# STM32H573 register map
File version: 0.4
CPU: CM33 r0p0, little endian, MPU, FPU, 4 interrupt priority bits
Registers are 32-bit, read-write, reset 0x0 unless marked. A register's access mark holds for its fields unless they carry their own. Offsets are from the block's base; [hi:lo] are bit positions; {n}, {i} and the like mark numbered series.

## RCC (part 2 of 2) — Reset and clock controller
Base 0x44020C00
Same registers: SEC_RCC 0x54020C00
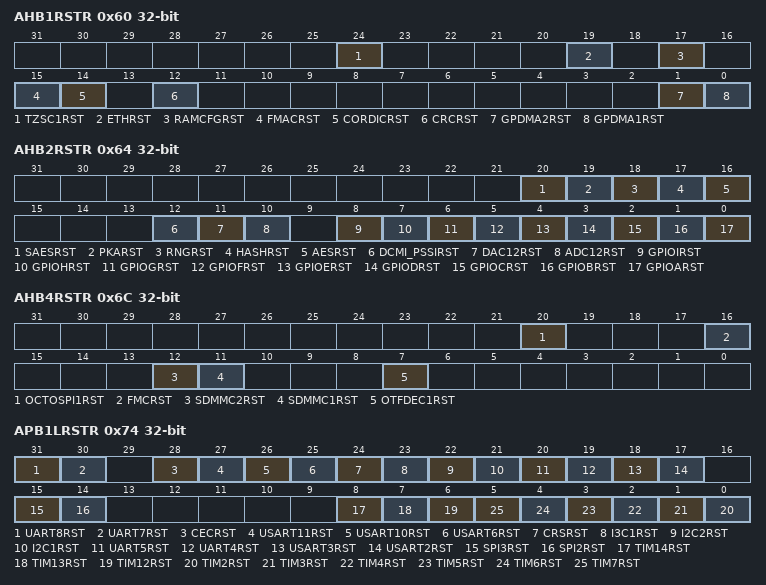
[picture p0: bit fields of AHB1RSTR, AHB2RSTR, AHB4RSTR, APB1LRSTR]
0x60 AHB1RSTR — RCC AHB1 reset register
  [24] TZSC1RST — TZSC1 reset Set and reset by software
  [19] ETHRST — ETHRST block reset Set and reset by software
  [17] RAMCFGRST — RAMCFG block reset Set and reset by software.
  [15] FMACRST — FMAC block reset Set and reset by software.
  [14] CORDICRST — CORDIC block reset Set and reset by software.
  [12] CRCRST — CRC block reset Set and reset by software.
  [1] GPDMA2RST — GPDMA2 block reset Set and reset by software.
  [0] GPDMA1RST — GPDMA1 block reset Set and reset by software.
0x64 AHB2RSTR — RCC AHB2 peripheral reset register
  [20] SAESRST — SAES block reset Set and reset by software.
  [19] PKARST — PKA block reset Set and reset by software.
  [18] RNGRST — RNG block reset Set and reset by software.
  [17] HASHRST — HASH block reset Set and reset by software.
  [16] AESRST — AES block reset Set and reset by software.
  [12] DCMI_PSSIRST — digital camera interface block reset (DCMI or PSSI depending which interface is active) Set and reset by software.
  [11] DAC12RST — DAC block reset Set and reset by software.
  [10] ADC12RST — ADC1 and 2 blocks reset Set and reset by software.
  [8] GPIOIRST — GPIOI block reset Set and reset by software.
  [7] GPIOHRST — GPIOH block reset Set and reset by software.
  [6] GPIOGRST — GPIOG block reset Set and reset by software.
  [5] GPIOFRST — GPIOF block reset Set and reset by software.
  [4] GPIOERST — GPIOE block reset Set and reset by software.
  [3] GPIODRST — GPIOD block reset Set and reset by software.
  [2] GPIOCRST — GPIOC block reset Set and reset by software.
  [1] GPIOBRST — GPIOB block reset Set and reset by software.
  [0] GPIOARST — GPIOA block reset Set and reset by software.
0x6C AHB4RSTR — RCC AHB4 peripheral reset register
  [20] OCTOSPI1RST — OCTOSPI1 block reset Set and reset by software.
  [16] FMCRST — FMC block reset Set and reset by software.
  [12] SDMMC2RST — SDMMC2 and SDMMC2 delay blocks reset Set and reset by software.
  [11] SDMMC1RST — SDMMC1 and SDMMC1 delay blocks reset Set and reset by software.
  [7] OTFDEC1RST — OTFDEC1 block reset Set and reset by software.
0x74 APB1LRSTR — RCC APB1 peripheral low reset register
  [31] UART8RST — UART8 block reset Set and reset by software.
  [30] UART7RST — UART7 block reset Set and reset by software.
  [28] CECRST — HDMI-CEC block reset Set and reset by software.
  [27] USART11RST — USART11 block reset Set and reset by software.
  [26] USART10RST — USART10 block reset Set and reset by software.
  [25] USART6RST — USART6 block reset Set and reset by software.
  [24] CRSRST — CRS block reset Set and reset by software.
  [23] I3C1RST — I3C1 block reset Set and reset by software.
  [22] I2C2RST — I2C2 block reset Set and reset by software.
  [21] I2C1RST — I2C1 block reset Set and reset by software.
  [20] UART5RST — UART5 block reset Set and reset by software.
  [19] UART4RST — UART4 block reset Set and reset by software.
  [18] USART3RST — USART3 block reset Set and reset by software.
  [17] USART2RST — USART2 block reset Set and reset by software.
  [15] SPI3RST — SPI3 block reset Set and reset by software.
  [14] SPI2RST — SPI2 block reset Set and reset by software.
  [8] TIM14RST — TIM14 block reset Set and reset by software.
  [7] TIM13RST — TIM13 block reset t Set and reset by software.
  [6] TIM12RST — TIM12 block reset Set and reset by software.
  [n-2] TIM{n}RST (n=2..7) — TIM{n} block reset Set and reset by software.
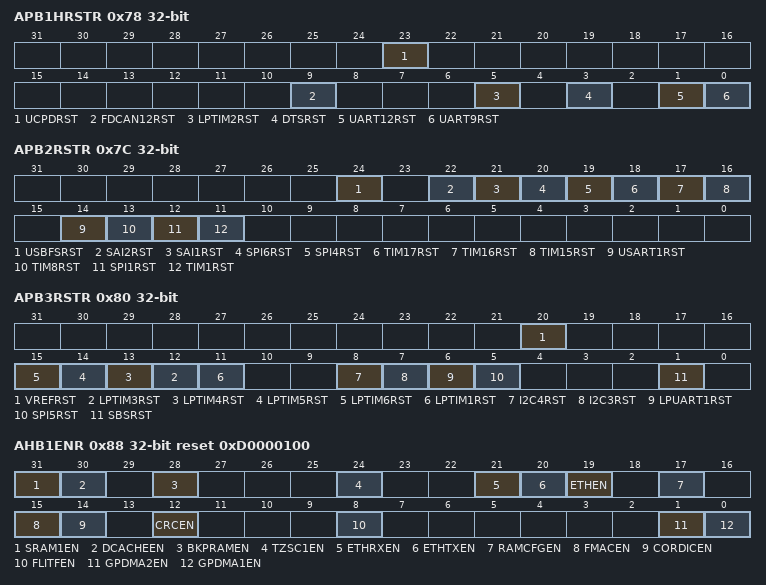
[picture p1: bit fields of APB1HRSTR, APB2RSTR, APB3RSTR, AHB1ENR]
0x78 APB1HRSTR — RCC APB1 peripheral high reset register
  [23] UCPDRST — UCPD block reset Set and reset by software.
  [9] FDCAN12RST — FDCAN1 and FDCAN2 blocks reset Set and reset by software.
  [5] LPTIM2RST — LPTIM2 block reset Set and reset by software.
  [3] DTSRST — DTS block reset Set and reset by software.
  [1] UART12RST — UART12 block reset Set and reset by software.
  [0] UART9RST — UART9 block reset Set and reset by software.
0x7C APB2RSTR — RCC APB2 peripheral reset register
  [24] USBFSRST — USBFS block reset Set and reset by software.
  [22] SAI2RST — SAI2 block reset Set and reset by software.
  [21] SAI1RST — SAI1 block reset Set and reset by software.
  [20] SPI6RST — SPI6 block reset Set and reset by software.
  [19] SPI4RST — SPI4 block reset Set and reset by software.
  [18] TIM17RST — TIM17 block reset Set and reset by software.
  [17] TIM16RST — TIM16 block reset Set and reset by software.
  [16] TIM15RST — TIM15 block reset Set and reset by software.
  [14] USART1RST — USART1 block reset Set and reset by software.
  [13] TIM8RST — TIM8 block reset Set and reset by software.
  [12] SPI1RST — SPI1 block reset Set and reset by software.
  [11] TIM1RST — TIM1 block reset Set and reset by software.
0x80 APB3RSTR — RCC APB4 peripheral reset register
  [20] VREFRST — VREF block reset Set and reset by software.
  [n+9] LPTIM{n}RST (n=3..6) — LPTIM{n} block reset Set and reset by software.
  [11] LPTIM1RST — LPTIM1 block reset Set and reset by software.
  [8] I2C4RST — I2C4 block reset Set and reset by software.
  [7] I2C3RST — I2C3 block reset Set and reset by software.
  [6] LPUART1RST — LPUART1 block reset Set and reset by software.
  [5] SPI5RST — SPI5 block reset Set and reset by software.
  [1] SBSRST — SBS block reset Set and reset by software.
0x88 AHB1ENR reset 0xD0000100 — RCC AHB1 peripherals clock register
  [31] SRAM1EN — SRAM1 clock enable Set and reset by software.
  [30] DCACHEEN — DCACHE clock enable Set and reset by software
  [28] BKPRAMEN — BKPRAM clock enable Set and reset by software
  [24] TZSC1EN — TZSC1 clock enable Set and reset by software
  [21] ETHRXEN — ETHRX clock enable Set and reset by software
  [20] ETHTXEN — ETHTX clock enable Set and reset by software
  [19] ETHEN — ETH clock enable Set and reset by software
  [17] RAMCFGEN — RAMCFG clock enable Set and reset by software.
  [15] FMACEN — FMAC clock enable Set and reset by software.
  [14] CORDICEN — CORDIC clock enable Set and reset by software.
  [12] CRCEN — CRC clock enable Set and reset by software.
  [8] FLITFEN — Flash interface clock enable Set and reset by software.
  [1] GPDMA2EN — GPDMA2 clock enable Set and reset by software.
  [0] GPDMA1EN — GPDMA1 clock enable Set and reset by software.
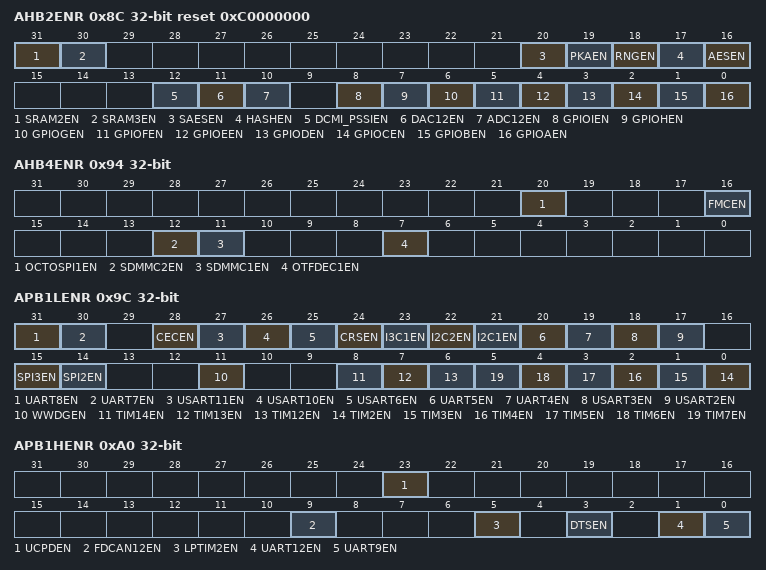
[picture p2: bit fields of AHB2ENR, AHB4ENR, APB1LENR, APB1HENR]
0x8C AHB2ENR reset 0xC0000000 — RCC AHB2 peripheral clock register
  [31] SRAM2EN — SRAM2 clock enable Set and reset by software.
  [30] SRAM3EN — SRAM3 clock enable Set and reset by software.
  [20] SAESEN — SAES clock enable Set and reset by software.
  [19] PKAEN — PKA clock enable Set and reset by software.
  [18] RNGEN — RNG clock enable Set and reset by software.
  [17] HASHEN — HASH clock enable Set and reset by software.
  [16] AESEN — AES clock enable Set and reset by software.
  [12] DCMI_PSSIEN — digital camera interface clock enable (DCMI or PSSI depending which interface is active) Set and reset by software.
  [11] DAC12EN — DAC clock enable Set and reset by software.
  [10] ADC12EN — ADC1 and 2 peripherals clock enabled Set and reset by software.
  [8] GPIOIEN — GPIOI clock enable Set and reset by software.
  [7] GPIOHEN — GPIOH clock enable Set and reset by software.
  [6] GPIOGEN — GPIOG clock enable Set and reset by software.
  [5] GPIOFEN — GPIOF clock enable Set and reset by software.
  [4] GPIOEEN — GPIOE clock enable Set and reset by software.
  [3] GPIODEN — GPIOD clock enable Set and reset by software.
  [2] GPIOCEN — GPIOC clock enable Set and reset by software.
  [1] GPIOBEN — GPIOB clock enable Set and reset by software.
  [0] GPIOAEN — GPIOA clock enable Set and reset by software.
0x94 AHB4ENR — RCC AHB4 peripheral clock register
  [20] OCTOSPI1EN — OCTOSPI1 clock enable Set and reset by software.
  [16] FMCEN — FMC clock enable Set and reset by software.
  [12] SDMMC2EN — SDMMC2 and SDMMC2 delay peripheral clock enabled Set and reset by software.
  [11] SDMMC1EN — SDMMC1 and SDMMC1 delay peripheral clock enable reset
  [7] OTFDEC1EN — OTFDEC1 clock enable Set and reset by software.
0x9C APB1LENR — RCC APB1 peripheral clock register
  [31] UART8EN — UART8 clock enable Set and reset by software.
  [30] UART7EN — UART7 clock enable Set and reset by software.
  [28] CECEN — HDMI-CEC clock enable Set and reset by software.
  [27] USART11EN — USART11 clock enable
  [26] USART10EN — USART10 clock enable Set and reset by software.
  [25] USART6EN — USART6 clock enable Set and reset by software.
  [24] CRSEN — CRS clock enable Set and reset by software.
  [23] I3C1EN — I3C1 clock enable Set and reset by software.
  [22] I2C2EN — I2C2 clock enable Set and reset by software.
  [21] I2C1EN — I2C1 clock enable Set and reset by software.
  [20] UART5EN — UART5 clock enable Set and reset by software.
  [19] UART4EN — UART4 clock enable Set and reset by software.
  [18] USART3EN — USART3 clock enable Set and reset by software.
  [17] USART2EN — USART2 clock enable Set and reset by software.
  [15] SPI3EN — SPI3 clock enable Set and reset by software.
  [14] SPI2EN — SPI2 clock enable Set and reset by software.
  [11] WWDGEN — WWDG clock enable Set and reset by software.
  [8] TIM14EN — TIM14 clock enable Set and reset by software.
  [7] TIM13EN — TIM13 clock enable Set and reset by software.
  [6] TIM12EN — TIM12 clock enable Set and reset by software.
  [n-2] TIM{n}EN (n=2..7) — TIM{n} clock enable Set and reset by software.
0xA0 APB1HENR — RCC APB1 peripheral clock register
  [23] UCPDEN — UCPD clock enable Set and reset by software.
  [9] FDCAN12EN — FDCAN1 and FDCAN2 peripheral clock enable Set and reset by software.
  [5] LPTIM2EN — LPTIM2 clock enable Set and reset by software.
  [3] DTSEN — DTS clock enable Set and reset by software.
  [1] UART12EN — UART12 clock enable Set and reset by software.
  [0] UART9EN — UART9 clock enable Set and reset by software.
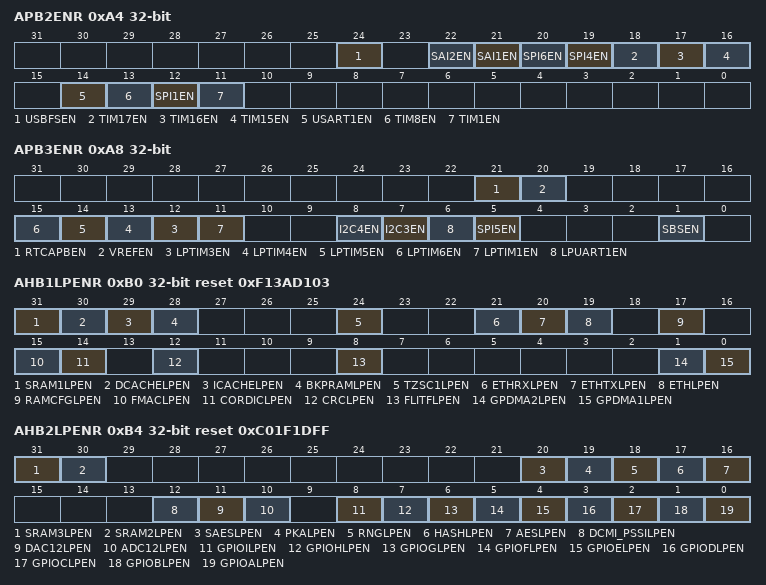
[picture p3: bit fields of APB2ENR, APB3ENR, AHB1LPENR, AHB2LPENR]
0xA4 APB2ENR — RCC APB2 peripheral clock register
  [24] USBFSEN — USBFS clock enable Set and reset by software.
  [22] SAI2EN — SAI2 clock enable Set and cleared by software.
  [21] SAI1EN — SAI1 clock enable Set and reset by software.
  [20] SPI6EN — SPI6 clock enable Set and reset by software.
  [19] SPI4EN — SPI4 clock enable Set and reset by software.
  [18] TIM17EN — TIM17 clock enable Set and reset by software.
  [17] TIM16EN — TIM16 clock enable Set and reset by software.
  [16] TIM15EN — TIM15 clock enable Set and reset by software.
  [14] USART1EN — USART1 clock enable Set and reset by software.
  [13] TIM8EN — TIM8 clock enable Set and reset by software.
  [12] SPI1EN — SPI1 clock enable Set and reset by software.
  [11] TIM1EN — TIM1 clock enable Set and reset by software.
0xA8 APB3ENR — RCC APB4 peripheral clock register
  [21] RTCAPBEN — RTC APB interface clock enable Set and reset by software.
  [20] VREFEN — VREF clock enable Set and reset by software.
  [n+9] LPTIM{n}EN (n=3..6) — LPTIM{n} clock enable Set and reset by software.
  [11] LPTIM1EN — LPTIM1 clock enable Set and reset by software.
  [8] I2C4EN — I2C4 clock enable Set and reset by software.
  [7] I2C3EN — I2C3 clock enable Set and reset by software.
  [6] LPUART1EN — LPUART1 clock enable Set and reset by software.
  [5] SPI5EN — SPI5 clock enable Set and reset by software.
  [1] SBSEN — SBS clock enable Set and reset by software.
0xB0 AHB1LPENR reset 0xF13AD103 — RCC AHB1 sleep clock register
  [31] SRAM1LPEN — SRAM1 clock enable during sleep mode Set and reset by software
  [30] DCACHELPEN — DCACHE clock enable during sleep mode Set and reset by software
  [29] ICACHELPEN — ICACHE clock enable during sleep mode Set and reset by software
  [28] BKPRAMLPEN — BKPRAM clock enable during sleep mode Set and reset by software
  [24] TZSC1LPEN — TZSC1 clock enable during sleep mode Set and reset by software
  [21] ETHRXLPEN — ETHRX clock enable during sleep mode Set and reset by software
  [20] ETHTXLPEN — ETHTX clock enable during sleep mode Set and reset by software
  [19] ETHLPEN — ETH clock enable during Sleep mode Set and reset by software
  [17] RAMCFGLPEN — RAMCFG clock enable during sleep mode Set and reset by software.
  [15] FMACLPEN — FMAC clock enable during sleep mode Set and reset by software.
  [14] CORDICLPEN — CORDIC clock enable during sleep mode Set and reset by software.
  [12] CRCLPEN — CRC clock enable during sleep mode Set and reset by software.
  [8] FLITFLPEN — Flash interface (FLITF) clock enable during sleep mode Set and reset by software.
  [1] GPDMA2LPEN — GPDMA2 clock enable during sleep mode Set and reset by software.
  [0] GPDMA1LPEN — GPDMA1 clock enable during sleep mode Set and reset by software.
0xB4 AHB2LPENR reset 0xC01F1DFF — RCC AHB2 sleep clock register
  [31] SRAM3LPEN — SRAM3 clock enable during sleep mode Set and reset by software.
  [30] SRAM2LPEN — SRAM2 clock enable during sleep mode Set and reset by software.
  [20] SAESLPEN — SAES clock enable during sleep mode Set and reset by software.
  [19] PKALPEN — PKA clock enable during sleep mode Set and reset by software.
  [18] RNGLPEN — RNG clock enable during sleep mode Set and reset by software.
  [17] HASHLPEN — HASH clock enable during sleep mode Set and reset by software.
  [16] AESLPEN — AES clock enable during sleep mode Set and reset by software.
  [12] DCMI_PSSILPEN — digital camera interface clock enable during sleep mode (DCMI or PSSI depending which interface is active) Set and reset by software.
  [11] DAC12LPEN — DAC clock enable during sleep mode Set and reset by software.
  [10] ADC12LPEN — ADC1 and 2 peripherals clock enable during sleep mode Set and reset by software.
  [8] GPIOILPEN — GPIOI clock enable during sleep mode Set and reset by software.
  [7] GPIOHLPEN — GPIOH clock enable during sleep mode Set and reset by software.
  [6] GPIOGLPEN — GPIOG clock enable during sleep mode Set and reset by software.
  [5] GPIOFLPEN — GPIOF clock enable during sleep mode Set and reset by software.
  [4] GPIOELPEN — GPIOE clock enable during sleep mode Set and reset by software.
  [3] GPIODLPEN — GPIOD clock enable during sleep mode Set and reset by software.
  [2] GPIOCLPEN — GPIOC clock enable during sleep mode Set and reset by software.
  [1] GPIOBLPEN — GPIOB clock enable during sleep mode Set and reset by software.
  [0] GPIOALPEN — GPIOA clock enable during sleep mode Set and reset by software.
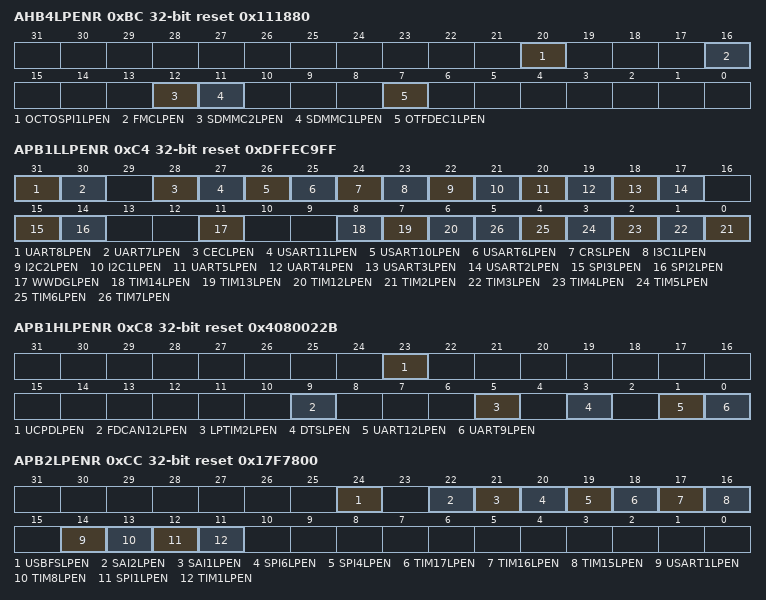
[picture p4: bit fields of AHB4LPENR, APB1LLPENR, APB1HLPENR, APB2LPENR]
0xBC AHB4LPENR reset 0x111880 — RCC AHB4 sleep clock register
  [20] OCTOSPI1LPEN — OCTOSPI1 clock enable during sleep mode Set and reset by software.
  [16] FMCLPEN — FMC clock enable during sleep mode Set and reset by software.
  [12] SDMMC2LPEN — SDMMC2 and SDMMC2 delay peripheral clock enable during sleep mode Set and reset by software.
  [11] SDMMC1LPEN — SDMMC1 and SDMMC1 delay peripheral clock enable during sleep mode Set and reset by software
  [7] OTFDEC1LPEN — OTFDEC1 clock enable during sleep mode Set and reset by software.
0xC4 APB1LLPENR reset 0xDFFEC9FF — RCC APB1 sleep clock register
  [31] UART8LPEN — UART8 clock enable during sleep mode Set and reset by software.
  [30] UART7LPEN — UART7 clock enable during sleep mode Set and reset by software.
  [28] CECLPEN — HDMI-CEC clock enable during sleep mode Set and reset by software.
  [27] USART11LPEN — USART11 clock enable during sleep mode Set and reset by software.
  [26] USART10LPEN — USART10 clock enable during sleep mode Set and reset by software.
  [25] USART6LPEN — USART6 clock enable during sleep mode Set and reset by software.
  [24] CRSLPEN — CRS clock enable during sleep mode Set and reset by software.
  [23] I3C1LPEN — I3C1 clock enable during sleep mode Set and reset by software.
  [22] I2C2LPEN — I2C2 clock enable during sleep mode Set and reset by software.
  [21] I2C1LPEN — I2C1 clock enable during sleep mode Set and reset by software.
  [20] UART5LPEN — UART5 clock enable during sleep mode Set and reset by software.
  [19] UART4LPEN — UART4 clock enable during sleep mode Set and reset by software.
  [18] USART3LPEN — USART3 clock enable during sleep mode Set and reset by software.
  [17] USART2LPEN — USART2 clock enable during sleep mode Set and reset by software.
  [15] SPI3LPEN — SPI3 clock enable during sleep mode Set and reset by software.
  [14] SPI2LPEN — SPI2 clock enable during sleep mode Set and reset by software.
  [11] WWDGLPEN — WWDG clock enable during sleep mode Set and reset by software.
  [8] TIM14LPEN — TIM14 clock enable during sleep mode Set and reset by software.
  [7] TIM13LPEN — TIM13 clock enable during sleep mode Set and reset by software.
  [6] TIM12LPEN — TIM12 clock enable during sleep mode Set and reset by software.
  [n-2] TIM{n}LPEN (n=2..7) — TIM{n} clock enable during sleep mode Set and reset by software.
0xC8 APB1HLPENR reset 0x4080022B — RCC APB1 sleep clock register
  [23] UCPDLPEN — UCPD clock enable during sleep mode Set and reset by software.
  [9] FDCAN12LPEN — FDCAN1 and FDCAN2 peripheral clock enable during sleep mode Set and reset by software.
  [5] LPTIM2LPEN — LPTIM2 clock enable during sleep mode Set and reset by software.
  [3] DTSLPEN — DTS clock enable during sleep mode Set and reset by software.
  [1] UART12LPEN — UART12 clock enable during sleep mode Set and reset by software.
  [0] UART9LPEN — UART9 clock enable during sleep mode Set and reset by software.
0xCC APB2LPENR reset 0x17F7800 — RCC APB2 sleep clock register
  [24] USBFSLPEN — USBFS clock enable during sleep mode Set and reset by software.
  [22] SAI2LPEN — SAI2 clock enable during sleep mode Set and reset by software.
  [21] SAI1LPEN — SAI1 clock enable during sleep mode Set and reset by software.
  [20] SPI6LPEN — SPI6 clock enable during sleep mode Set and reset by software.
  [19] SPI4LPEN — SPI4 clock enable during sleep mode Set and reset by software.
  [18] TIM17LPEN — TIM17 clock enable during sleep mode Set and reset by software.
  [17] TIM16LPEN — TIM16 clock enable during sleep mode Set and reset by software.
  [16] TIM15LPEN — TIM15 clock enable during sleep mode Set and reset by software.
  [14] USART1LPEN — USART1 clock enable during sleep mode Set and reset by software.
  [13] TIM8LPEN — TIM8 clock enable during sleep mode Set and reset by software.
  [12] SPI1LPEN — SPI1 clock enable during sleep mode Set and reset by software.
  [11] TIM1LPEN — TIM1 clock enable during sleep mode Set and reset by software.
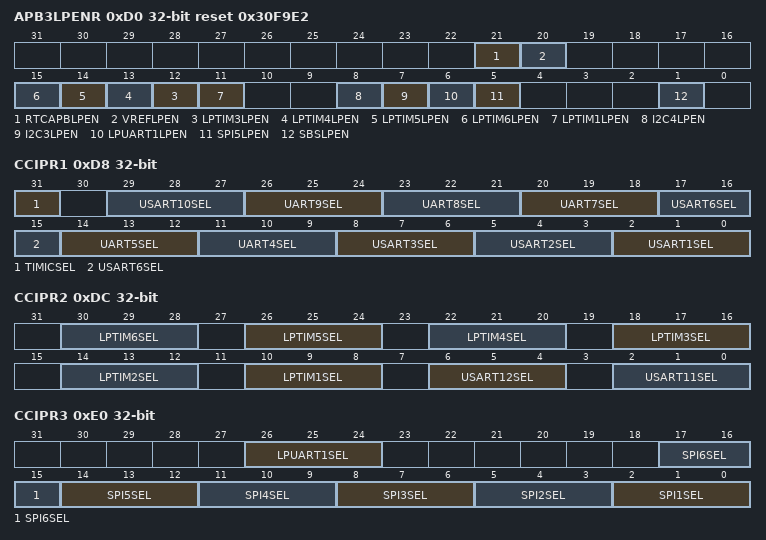
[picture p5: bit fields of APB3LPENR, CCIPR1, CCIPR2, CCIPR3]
0xD0 APB3LPENR reset 0x30F9E2 — RCC APB4 sleep clock register
  [21] RTCAPBLPEN — RTC APB interface clock enable during sleep mode Set and reset by software.
  [20] VREFLPEN — VREF clock enable during sleep mode Set and reset by software.
  [n+9] LPTIM{n}LPEN (n=3..6) — LPTIM{n} clock enable during sleep mode Set and reset by software.
  [11] LPTIM1LPEN — LPTIM1 clock enable during sleep mode Set and reset by software.
  [8] I2C4LPEN — I2C4 clock enable during sleep mode Set and reset by software.
  [7] I2C3LPEN — I2C3 clock enable during sleep mode Set and reset by software.
  [6] LPUART1LPEN — LPUART1 clock enable during sleep mode Set and reset by software.
  [5] SPI5LPEN — SPI5 clock enable during Slsleepeep mode Set and reset by software.
  [1] SBSLPEN — SBS clock enable during sleep mode Set and reset by software.
0xD8 CCIPR1 — RCC kernel clock configuration register
  [31] TIMICSEL — TIM12, TIM15 and LPTIM2 input capture source selection Set and reset by software.
  [29:27] USART10SEL — USART10 kernel clock source selection others: reserved, the kernel clock is disabled
  [26:24] UART9SEL — UART9 kernel clock source selection others: reserved, the kernel clock is disabled
  [23:21] UART8SEL — UART8 kernel clock source selection others: reserved, the kernel clock is disabled
  [20:18] UART7SEL — UART7 kernel clock source selection others: reserved, the kernel clock is disabled
  [17:15] USART6SEL — USART6 kernel clock source selection others: reserved, the kernel clock is disabled
  [14:12] UART5SEL — UART5 kernel clock source selection others: reserved, the kernel clock is disabled
  [11:9] UART4SEL — UART4 kernel clock source selection others: reserved, the kernel clock is disabled
  [8:6] USART3SEL — USART3 kernel clock source selection Set and reset by software. others: reserved, the kernel clock is disabled
  [5:3] USART2SEL — USART2 kernel clock source selection Set and reset by software. others: reserved, the kernel clock is disabled
  [2:0] USART1SEL — USART1 kernel clock source selection Set and reset by software. others: reserved, the kernel clock is disabled
0xDC CCIPR2 — RCC kernel clock configuration register
  [4n+6:4n+4] LPTIM{n}SEL (n=1..6) — LPTIM{n} kernel clock source selection others: reserved, the kernel clock is disabled
  [6:4] USART12SEL — USART12 kernel clock source selection Set and reset by software. others: reserved, the kernel clock is disabled
  [2:0] USART11SEL — USART11 kernel clock source selection Set and reset by software. others: reserved, the kernel clock is disabled
0xE0 CCIPR3 — RCC kernel clock configuration register
  [26:24] LPUART1SEL — LPUART1 kernel clock source selection others: reserved, the kernel clock is disabled
  [17:15] SPI6SEL — SPI6 kernel clock source selection others: reserved, the kernel clock is disabled
  [14:12] SPI5SEL — SPI5 kernel clock source selection others: reserved, the kernel clock is disabled
  [11:9] SPI4SEL — SPI4 kernel clock source selection others: reserved, the kernel clock is disabled
  [8:6] SPI3SEL — SPI3 kernel clock source selection Set and reset by software. others: reserved, the kernel clock is disabled
  [5:3] SPI2SEL — SPI2 kernel clock source selection Set and reset by software. others: reserved, the kernel clock is disabled
  [2:0] SPI1SEL — SPI1 kernel clock source selection Set and reset by software. others: reserved, the kernel clock is disabled
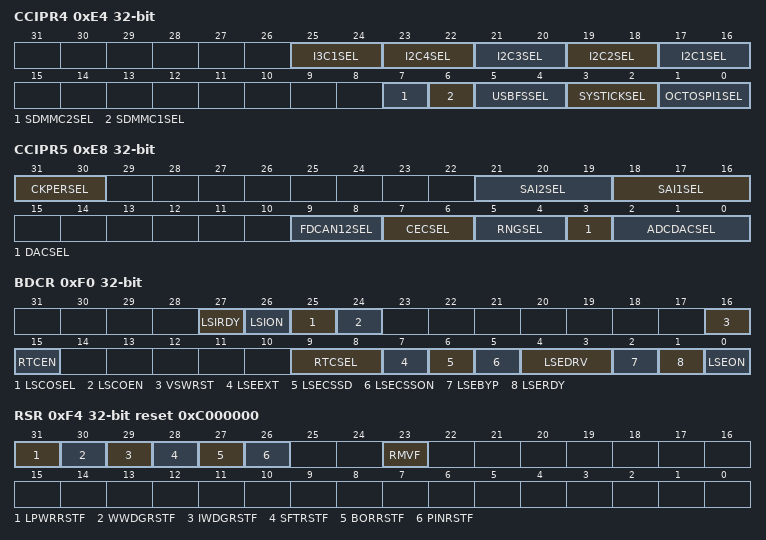
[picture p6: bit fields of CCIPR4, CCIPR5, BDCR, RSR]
0xE4 CCIPR4 — RCC kernel clock configuration register
  [25:24] I3C1SEL — I3C1 kernel clock source selection
  [2n+15:2n+14] I2C{n}SEL (n=1..4) — I2C{n} kernel clock source selection
  [7] SDMMC2SEL — SDMMC2 kernel clock source selection
  [6] SDMMC1SEL — SDMMC1 kernel clock source selection
  [5:4] USBFSSEL — USBFS kernel clock source selection
  [3:2] SYSTICKSEL — SYSTICK clock source selection Note: rcc_hclk frequency must be four times higher than lsi_ker_ck/lse_ck (period (LSI/LSE) ≥ 4 * period (HCLK).
  [1:0] OCTOSPI1SEL — OCTOSPI1 kernel clock source selection Set and reset by software.
0xE8 CCIPR5 — RCC kernel clock configuration register
  [31:30] CKPERSEL — per_ck clock source selection
  [21:19] SAI2SEL — SAI2 kernel clock source selection others: reserved, the kernel clock is disabled
  [18:16] SAI1SEL — SAI1 kernel clock source selection others: reserved, the kernel clock is disabled
  [9:8] FDCAN12SEL — FDCAN1 and FDCAN2 kernel clock source selection
  [7:6] CECSEL — HSMI-CEC kernel clock source selection
  [5:4] RNGSEL — RNG kernel clock source selection
  [3] DACSEL — DAC hold clock
  [2:0] ADCDACSEL — ADC and DAC kernel clock source selection others: reserved, the kernel clock is disabled
0xF0 BDCR — RCC Backup domain control register
  [27] LSIRDY — LSI oscillator ready Set and cleared by hardware to indicate when the LSI oscillator is stable. After the LSION bit is cleared, LSIRDY goes low after three internal low-speed oscillator clock cycles. This bit is set when the LSI is used by IWDG or RTC, even if LSION = 0.
  [26] LSION — LSI oscillator enable Set and cleared by software.
  [25] LSCOSEL — Low-speed clock output selection Set and cleared by software.
  [24] LSCOEN — Low-speed clock output (LSCO) enable Set and cleared by software.
  [16] VSWRST — VSwitch domain software reset Set and reset by software.
  [15] RTCEN — RTC clock enable Set and reset by software.
  [9:8] RTCSEL — RTC clock source selection Set by software to select the clock source for the RTC. These bits can be written only one time (except in case of failure detection on LSE). These bits must be written before LSECSSON is enabled. The VSWRST bit can be used to reset them, then it can be written one time again. If HSE is selected as RTC clock, this clock is lost when the system is in Stop mode or in case of a pin reset (NRST).
  [7] LSEEXT — low-speed external clock type in bypass mode Set and reset by software to select the external clock type (analog or digital). The external clock must be enabled with the LSEON bit, to be used by the device. The LSEEXT bit can be written only if the LSE oscillator is disabled.
  [6] LSECSSD — LSE clock security system failure detection Set by hardware to indicate when a failure has been detected by the clock security system on the external 32 kHz oscillator.
  [5] LSECSSON — LSE clock security system enable Set by software to enable the clock security system on 32 kHz oscillator. LSECSSON must be enabled after LSE is enabled (LSEON enabled) and ready (LSERDY set by hardware) and after RTCSEL is selected. Once enabled, this bit cannot be disabled, except after a LSE failure detection (LSECSSD = 1). In that case the software must disable LSECSSON.
  [4:3] LSEDRV — LSE oscillator driving capability Set by software to select the driving capability of the LSE oscillator. These bit can be written only if LSE oscillator is disabled (LSEON = 0 and LSERDY = 0).
  [2] LSEBYP — LSE oscillator bypass Set and reset by software to bypass oscillator in debug mode. This bit must not be written when the LSE is enabled (by LSEON) or ready (LSERDY = 1)
  [1] LSERDY — LSE oscillator ready Set and reset by hardware to indicate when the LSE is stable. This bit needs 6 cycles of lse_ck clock to fall down after LSEON has been set to 0.
  [0] LSEON — LSE oscillator enabled Set and reset by software.
0xF4 RSR reset 0xC000000 — RCC reset status register
  [31] LPWRRSTF — Low-power reset flag Set by hardware when a reset occurs due to Stop or Standby mode entry, whereas the corresponding nRST_STOP, nRST_STBY option bit is cleared. Cleared by writing to the RMVF bit.
  [30] WWDGRSTF — window watchdog reset flag Reset by software by writing the RMVF bit. Set by hardware when a window watchdog reset occurs.
  [29] IWDGRSTF — independent watchdog reset flag Reset by software by writing the RMVF bit. Set by hardware when an independent watchdog reset occurs.
  [28] SFTRSTF — system reset from CPU reset flag Reset by software by writing the RMVF bit. Set by hardware when the system reset is due to CPU.The CPU can generate a system reset by writing SYSRESETREQ bit of AIRCR register of the core M33.
  [27] BORRSTF — BOR reset flag Reset by software by writing the RMVF bit. Set by hardware when a BOR reset occurs (pwr_bor_rst).
  [26] PINRSTF — pin reset flag (NRST) Reset by software by writing the RMVF bit. Set by hardware when a reset from pin occurs.
  [23] RMVF — remove reset flag Set and reset by software to reset the value of the reset flags.
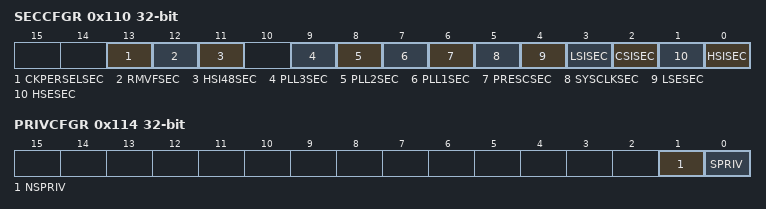
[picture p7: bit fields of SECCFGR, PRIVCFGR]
0x110 SECCFGR — RCC secure configuration register
  [13] CKPERSELSEC — per_ck selection security Set and reset by software.
  [12] RMVFSEC — Remove reset flag security Set and reset by software.
  [11] HSI48SEC — HSI48 clock configuration and status bits security Set and reset by software.
  [9] PLL3SEC — PLL3 clock configuration and status bits security Set and reset by software.
  [8] PLL2SEC — PLL2 clock configuration and status bits security Set and reset by software.
  [7] PLL1SEC — PLL1 clock configuration and status bits security Set and reset by software.
  [6] PRESCSEC — AHBx/APBx prescaler configuration bits security Set and reset by software.
  [5] SYSCLKSEC — SYSCLK clock selection, STOPWUCK bit, clock output on MCO configuration security Set and reset by software.
  [4] LSESEC — LSE clock configuration and status bits security Set and reset by software.
  [3] LSISEC — LSI clock configuration and status bits security Set and reset by software.
  [2] CSISEC — CSI clock configuration and status bits security Set and reset by software.
  [1] HSESEC — HSE clock configuration bits, status bits and HSE_CSS security Set and reset by software.
  [0] HSISEC — HSI clock configuration and status bits security Set and reset by software.
0x114 PRIVCFGR — RCC privilege configuration register
  [1] NSPRIV — RCC non-secure functions privilege configuration Set and reset by software. This bit can be written only by privileged access, secure or non-secure.
  [0] SPRIV — RCC secure functions privilege configuration Set and reset by software. This bit can be written only by a secure privileged access.
